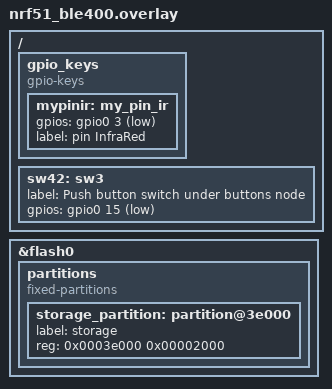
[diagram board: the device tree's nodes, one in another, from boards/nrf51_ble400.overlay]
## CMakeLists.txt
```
# SPDX-License-Identifier: Apache-2.0

cmake_minimum_required(VERSION 3.20.0)

find_package(Zephyr REQUIRED HINTS $ENV{ZEPHYR_BASE})
project(zephyr_template)

target_sources(app PRIVATE src/main.c)
```

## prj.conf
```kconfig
CONFIG_GPIO=y


#Log immediate
CONFIG_LOG=y
CONFIG_LOG_MODE_DEFERRED=n
CONFIG_LOG_MODE_IMMEDIATE=y
#make LOG_DBG outputs visible
CONFIG_LOG_DEFAULT_LEVEL=4
```

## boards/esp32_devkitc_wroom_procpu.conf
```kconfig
# CONFIG_WIFI=y

# CONFIG_NETWORKING=y
# CONFIG_NET_L2_ETHERNET=y
# CONFIG_ESP32_WIFI_STA_AUTO_DHCPV4=y
# CONFIG_NET_IPV6=n
# CONFIG_NET_IPV4=y

# CONFIG_NET_DHCPV4=y
# CONFIG_NET_LOG=yr
```

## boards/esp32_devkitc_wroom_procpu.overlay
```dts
/ {

     aliases {
             led0 = &myled0;
     };

     leds {
             compatible = "gpio-leds";
             myled0: led_0 {
                     gpios = <&gpio0 2 GPIO_ACTIVE_LOW>;
             };
     };

     wifi {
         status = "okay";
     };

};
```

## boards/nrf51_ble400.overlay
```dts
/ {

  gpio_keys {
    /* Push button switch 0 KEY1 */
    compatible = "gpio-keys";
    mypinir: my_pin_ir {
      gpios = <&gpio0 3 (GPIO_PULL_UP | GPIO_ACTIVE_LOW)>;
      label = "pin InfraRed";
      status = "okay";
    };
  };

  sw42: sw3 {
    label = "Push button switch under buttons node";
    gpios = <&gpio0 15 (GPIO_PULL_UP | GPIO_ACTIVE_LOW)>;
    // debounce-interval = <20>;
  };


};

&flash0 {
  partitions {
    compatible = "fixed-partitions";
    #address-cells = <1>;
    #size-cells = <1>;
    storage_partition: partition@3e000 {
      label = "storage";
      reg = <0x0003e000 0x00002000>;
    };
  };
};
```

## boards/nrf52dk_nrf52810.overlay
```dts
/delete-node/ &storage_partition;

&flash0 {
  partitions {
    /* Set 3KB of storage at the end of 128KB flash */
    storage_partition: partition@1f400 {
      label = "storage";
      reg = <0x0001f400 DT_SIZE_K(3)>;
    };
  };
};

/ {


  aliases {
    button12 = &button0;
  };    


  button12: button0 {
    label = "Push button switch under buttons node";
    gpios = <&gpio0 13 (GPIO_PULL_UP | GPIO_ACTIVE_LOW)>;
    debounce-interval = <0>;
  };
  
};
```

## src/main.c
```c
/*
 * Zephyr project template 
 * Marcelo Aleksandravicius - Jul 31 2024
 *
 * 
*/
#include <stdio.h>
#include <zephyr/drivers/gpio.h>
#include <zephyr/kernel.h>
#include <zephyr/logging/log.h>

LOG_MODULE_REGISTER(main);


#define LED0_NODE DT_ALIAS(led0)


static const struct gpio_dt_spec led = GPIO_DT_SPEC_GET(LED0_NODE, gpios);

int main(void) {
  int ret;
  bool led_state = true;

  if (!gpio_is_ready_dt(&led)) {
    LOG_ERR("Error, gpio is not ready\n");
    return 0;
  }
  // Log was configured to be instantenous and also to show debug messages.
  // Log was configured to be instantaneous and also to show debug messages.
  LOG_DBG("LED configured and ready to blink\n");
  while (1) {
    ret = gpio_pin_toggle_dt(&led);
    if (ret < 0) {
      LOG_ERR("Error toggling led\n");
      return 0;
    }

    led_state = !led_state;
    
    k_msleep(1000);
  }
  return 0;
}
```
